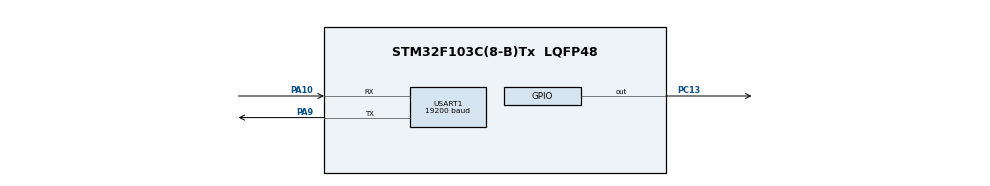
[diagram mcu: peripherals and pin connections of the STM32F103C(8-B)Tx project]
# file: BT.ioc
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FREERTOS.Queues01=Queue01,8,uint8_t,0,Dynamic,NULL,NULL
FREERTOS.Tasks01=Sender1,24,256,StartSender1,Default,NULL,Dynamic,NULL,NULL;Receiver,32,256,StartReceiver,Default,NULL,Dynamic,NULL,NULL;Sender2,24,256,StartSender2,Default,NULL,Dynamic,NULL,NULL
FREERTOS.configTOTAL_HEAP_SIZE=4000
FREERTOS.configUSE_NEWLIB_REENTRANT=1
Mcu.Family=STM32F1
Mcu.Name=STM32F103C(8-B)Tx
Mcu.Package=LQFP48
NVIC.PriorityGroup=NVIC_PRIORITYGROUP_4
NVIC.TIM3_IRQn=true\:15\:0\:false\:false\:true\:false\:false\:true\:true
NVIC.TimeBase=TIM3_IRQn
NVIC.TimeBaseIP=TIM3
PA10.Mode=Asynchronous
PA10.Signal=USART1_RX
PA13.Mode=Serial_Wire
PA13.Signal=SYS_JTMS-SWDIO
PA14.Mode=Serial_Wire
PA14.Signal=SYS_JTCK-SWCLK
PA9.Mode=Asynchronous
PA9.Signal=USART1_TX
PC13-TAMPER-RTC.Signal=GPIO_Output
PD0-OSC_IN.Mode=HSE-External-Oscillator
PD0-OSC_IN.Signal=RCC_OSC_IN
PD1-OSC_OUT.Mode=HSE-External-Oscillator
PD1-OSC_OUT.Signal=RCC_OSC_OUT
ProjectManager.HeapSize=0x200
ProjectManager.StackSize=0x400
ProjectManager.TargetToolchain=STM32CubeIDE
RCC.APB1Freq_Value=8000000
RCC.APB2Freq_Value=8000000
USART1.BaudRate=19200
USART1.VirtualMode=VM_ASYNC
VP_FREERTOS_VS_CMSIS_V2.Mode=CMSIS_V2
VP_SYS_VS_tim3.Mode=TIM3
board=custom

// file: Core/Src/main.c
/* USER CODE BEGIN Header */
/**
  ******************************************************************************
  * @file           : main.c
  * @brief          : Main program body
  ******************************************************************************
  * @attention
  *
  * Copyright (c) 2022 STMicroelectronics.
  * All rights reserved.
  *
  * This software is licensed under terms that can be found in the LICENSE file
  * in the root directory of this software component.
  * If no LICENSE file comes with this software, it is provided AS-IS.
  *
  ******************************************************************************
  */
/* USER CODE END Header */
#include "main.h"
#include "cmsis_os.h"

/* USER CODE BEGIN Includes */
#include "string.h"
#include "stdlib.h"
/* USER CODE END Includes */

UART_HandleTypeDef huart1;

/* Definitions for Sender1 */
osThreadId_t Sender1Handle;
const osThreadAttr_t Sender1_attributes = {
  .name = "Sender1",
  .stack_size = 256 * 4,
  .priority = (osPriority_t) osPriorityNormal,
};
/* Definitions for Receiver */
osThreadId_t ReceiverHandle;
const osThreadAttr_t Receiver_attributes = {
  .name = "Receiver",
  .stack_size = 256 * 4,
  .priority = (osPriority_t) osPriorityAboveNormal,
};
/* Definitions for Sender2 */
osThreadId_t Sender2Handle;
const osThreadAttr_t Sender2_attributes = {
  .name = "Sender2",
  .stack_size = 256 * 4,
  .priority = (osPriority_t) osPriorityNormal,
};
/* Definitions for Queue01 */
osMessageQueueId_t Queue01Handle;
const osMessageQueueAttr_t Queue01_attributes = {
  .name = "Queue01"
};

void SystemClock_Config(void);
static void MX_GPIO_Init(void);
static void MX_USART1_UART_Init(void);
void StartSender1(void *argument);
void StartReceiver(void *argument);
void StartSender2(void *argument);

/* USER CODE BEGIN PFP */
void un_monitor(char *texto, size_t tam);
void StartSender1(void *argument);
/* USER CODE END PFP */

int main(void)
{

  /* MCU Configuration--------------------------------------------------------*/

  /* Reset of all peripherals, Initializes the Flash interface and the Systick. */
  HAL_Init();

  /* Configure the system clock */
  SystemClock_Config();

  /* Initialize all configured peripherals */
  MX_GPIO_Init();
  MX_USART1_UART_Init();

  /* Init scheduler */
  osKernelInitialize();

  /* Create the queue(s) */
  /* creation of Queue01 */
  Queue01Handle = osMessageQueueNew (8, sizeof(uint8_t), &Queue01_attributes);

  /* Create the thread(s) */
  /* creation of Sender1 */
  Sender1Handle = osThreadNew(StartSender1, NULL, &Sender1_attributes);

  /* creation of Receiver */
  ReceiverHandle = osThreadNew(StartReceiver, NULL, &Receiver_attributes);

  /* creation of Sender2 */
  Sender2Handle = osThreadNew(StartSender2, NULL, &Sender2_attributes);

  /* Start scheduler */
  osKernelStart();

  /* We should never get here as control is now taken by the scheduler */
  /* Infinite loop */
  while (1)
  {

  }
}

void SystemClock_Config(void)
{
  RCC_OscInitTypeDef RCC_OscInitStruct = {0};
  RCC_ClkInitTypeDef RCC_ClkInitStruct = {0};

  /** Initializes the RCC Oscillators according to the specified parameters
  * in the RCC_OscInitTypeDef structure.
  */
  RCC_OscInitStruct.OscillatorType = RCC_OSCILLATORTYPE_HSI;
  RCC_OscInitStruct.HSIState = RCC_HSI_ON;
  RCC_OscInitStruct.HSICalibrationValue = RCC_HSICALIBRATION_DEFAULT;
  RCC_OscInitStruct.PLL.PLLState = RCC_PLL_NONE;
  if (HAL_RCC_OscConfig(&RCC_OscInitStruct) != HAL_OK)
  {
    Error_Handler();
  }

  /** Initializes the CPU, AHB and APB buses clocks
  */
  RCC_ClkInitStruct.ClockType = RCC_CLOCKTYPE_HCLK|RCC_CLOCKTYPE_SYSCLK
                              |RCC_CLOCKTYPE_PCLK1|RCC_CLOCKTYPE_PCLK2;
  RCC_ClkInitStruct.SYSCLKSource = RCC_SYSCLKSOURCE_HSI;
  RCC_ClkInitStruct.AHBCLKDivider = RCC_SYSCLK_DIV1;
  RCC_ClkInitStruct.APB1CLKDivider = RCC_HCLK_DIV1;
  RCC_ClkInitStruct.APB2CLKDivider = RCC_HCLK_DIV1;

  if (HAL_RCC_ClockConfig(&RCC_ClkInitStruct, FLASH_LATENCY_0) != HAL_OK)
  {
    Error_Handler();
  }
}

static void MX_USART1_UART_Init(void)
{

  huart1.Instance = USART1;
  huart1.Init.BaudRate = 19200;
  huart1.Init.WordLength = UART_WORDLENGTH_8B;
  huart1.Init.StopBits = UART_STOPBITS_1;
  huart1.Init.Parity = UART_PARITY_NONE;
  huart1.Init.Mode = UART_MODE_TX_RX;
  huart1.Init.HwFlowCtl = UART_HWCONTROL_NONE;
  huart1.Init.OverSampling = UART_OVERSAMPLING_16;
  if (HAL_UART_Init(&huart1) != HAL_OK)
  {
    Error_Handler();
  }

}

static void MX_GPIO_Init(void)
{
  GPIO_InitTypeDef GPIO_InitStruct = {0};

  /* GPIO Ports Clock Enable */
  __HAL_RCC_GPIOC_CLK_ENABLE();
  __HAL_RCC_GPIOD_CLK_ENABLE();
  __HAL_RCC_GPIOA_CLK_ENABLE();

  /*Configure GPIO pin Output Level */
  HAL_GPIO_WritePin(GPIOC, GPIO_PIN_13, GPIO_PIN_RESET);

  /*Configure GPIO pin : PC13 */
  GPIO_InitStruct.Pin = GPIO_PIN_13;
  GPIO_InitStruct.Mode = GPIO_MODE_OUTPUT_PP;
  GPIO_InitStruct.Pull = GPIO_NOPULL;
  GPIO_InitStruct.Speed = GPIO_SPEED_FREQ_LOW;
  HAL_GPIO_Init(GPIOC, &GPIO_InitStruct);

}

/* USER CODE BEGIN 4 */
void un_monitor(char *texto, size_t tam) {
	HAL_UART_Transmit(&huart1, (uint8_t*) texto, tam, 1000);
	HAL_GPIO_TogglePin(GPIOC, GPIO_PIN_13);
}

/* USER CODE END 4 */

void StartSender1(void *argument)
{
  /* USER CODE BEGIN 5 */
	char my_name[] = "Sender_1\n";
	uint8_t x = 0;
	/* Infinite loop */
	for (;;) {
		un_monitor(my_name, strlen(my_name));
		osMessageQueuePut(Queue01Handle, &x, 0, 200);
		x++;
		osDelay(1000);
	}
  /* USER CODE END 5 */
}

void StartReceiver(void *argument)
{
  /* USER CODE BEGIN StartReceiver */
  /* Infinite loop */
	char my_name[] = "Receiver\n";
	uint8_t x;
	char num_txt[5];
	char msg_error[] = "Error\n";
	osStatus_t ret_state;
	for(;;)
	{
		un_monitor(my_name, strlen(my_name));
		ret_state = osMessageQueueGet(Queue01Handle, &x, NULL, osWaitForever); // 2000);
		if (ret_state) {
			un_monitor(msg_error, strlen(msg_error));
		}
		else {
			itoa(x, num_txt, 10);
			un_monitor(num_txt, strlen(num_txt));
		}
	}
  /* USER CODE END StartReceiver */
}

void StartSender2(void *argument)
{
  /* USER CODE BEGIN StartSender2 */
	char my_name[] = "Sender_2\n";
	uint8_t x = 0;
	/* Infinite loop */
	for (;;) {
		un_monitor(my_name, strlen(my_name));
		osMessageQueuePut(Queue01Handle, &x, 0, 200);
		x++;
		osDelay(1000);
	}
  /* USER CODE END StartSender2 */
}

void HAL_TIM_PeriodElapsedCallback(TIM_HandleTypeDef *htim)
{
  if (htim->Instance == TIM3) {
    HAL_IncTick();
  }
}

void Error_Handler(void)
{
  __disable_irq();
  while (1)
  {
  }
}
